VERSION ""

NS_ :

BS_:

BU_:

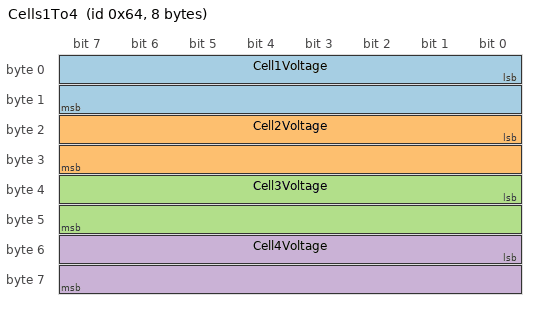
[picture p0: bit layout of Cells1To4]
BO_ 100 Cells1To4: 8 Vector__XXX
 SG_ Cell1Voltage : 0|16@1+ (1,0) [0|0] "mV" Vector__XXX
 SG_ Cell2Voltage : 16|16@1+ (1,0) [0|0] "mV" Vector__XXX
 SG_ Cell3Voltage : 32|16@1+ (1,0) [0|0] "mV" Vector__XXX
 SG_ Cell4Voltage : 48|16@1+ (1,0) [0|0] "mV" Vector__XXX

BO_ 101 Cells5To6: 4 Vector__XXX
 SG_ Cell5Voltage : 0|16@1+ (1,0) [0|0] "mV" Vector__XXX
 SG_ Cell6Voltage : 16|16@1+ (1,0) [0|0] "mV" Vector__XXX

BO_ 102 RegOutCurrent: 2 Vector__XXX
 SG_ regOutCurrent : 0|16@1+ (1,0) [0|0] "mA" Vector__XXX

BO_ 103 VbatOutCurrent: 4 Vector__XXX
 SG_ vbatOutCurrent : 0|32@1+ (1,0) [0|0] "mA" Vector__XXX

BA_DEF_  "BusType" STRING ;
BA_DEF_DEF_  "BusType" "CAN";
